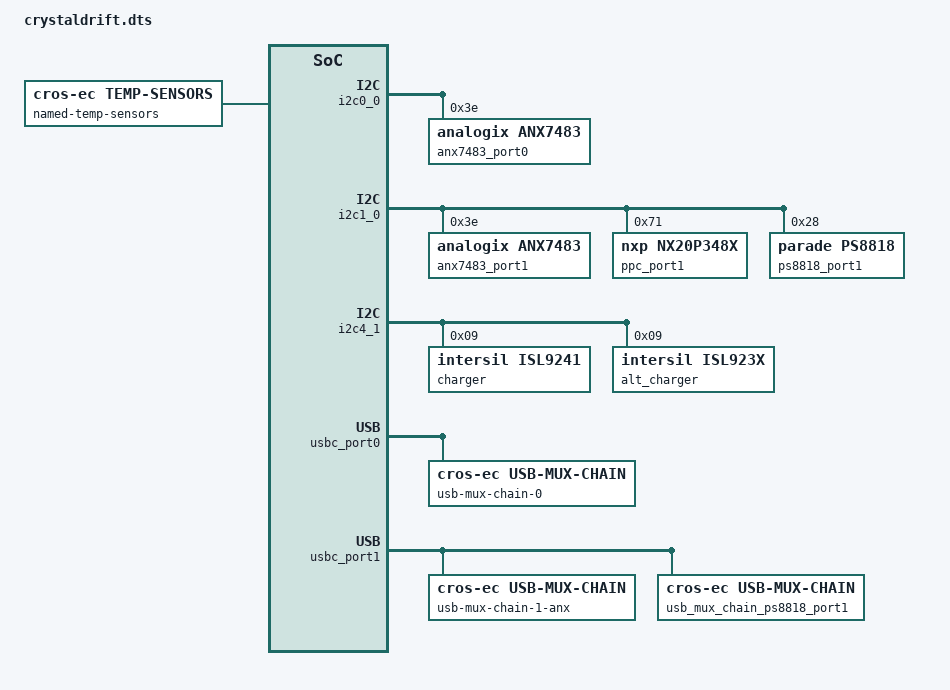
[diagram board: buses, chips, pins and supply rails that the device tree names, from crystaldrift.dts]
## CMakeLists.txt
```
# Copyright 2021 The ChromiumOS Authors
# Use of this source code is governed by a BSD-style license that can be
# found in the LICENSE file.

cmake_minimum_required(VERSION 3.13.1)

find_package(Zephyr REQUIRED HINTS "${ZEPHYR_BASE}")

zephyr_include_directories("${CMAKE_CURRENT_SOURCE_DIR}/include")

zephyr_library_sources("src/common.c")
zephyr_library_sources("src/i2c_policy.c")
zephyr_library_sources("src/power_signals.c")

zephyr_library_sources_ifdef(CONFIG_PLATFORM_EC_USBC
	"src/usb_pd_policy.c"
	"src/usb_mux_config.c"
	"src/usbc_config.c")
zephyr_library_sources_ifdef(CONFIG_PLATFORM_EC_LED_COMMON
	"src/led.c")
zephyr_library_sources_ifdef(CONFIG_PLATFORM_EC_AMD_STT
	"src/stt.c")

if(DEFINED CONFIG_BOARD_SKYRIM)
	project(skyrim)
	add_subdirectory(skyrim)
endif()

if(DEFINED CONFIG_BOARD_WINTERHOLD)
	project(winterhold)
	add_subdirectory(winterhold)
endif()

if(DEFINED CONFIG_BOARD_FROSTFLOW)
	project(frostflow)
	add_subdirectory(frostflow)
endif()

if(DEFINED CONFIG_BOARD_CRYSTALDRIFT)
	project(crystaldrift)
	add_subdirectory(crystaldrift)
endif()

if(DEFINED CONFIG_BOARD_MARKARTH)
	project(markarth)
	add_subdirectory(markarth)
endif()
```

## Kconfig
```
# Copyright 2021 The ChromiumOS Authors
# Use of this source code is governed by a BSD-style license that can be
# found in the LICENSE file.

config BOARD_SKYRIM
	bool "Google Skyrim Board"
	help
	  Build Google Skyrim reference board.  This board uses an AMD SoC
	  and NPCX9 EC

config BOARD_WINTERHOLD
	bool "Google Winterhold Board"
	help
	  Build Google Winterhold reference board.  This board uses an AMD SoC
	  and NPCX9 EC

config BOARD_FROSTFLOW
	bool "Google Frostflow Board"
	help
	  Build Google Frostflow reference board.  This board uses an AMD SoC
	  and NPCX9 EC

config BOARD_CRYSTALDRIFT
	bool "Google Crystaldrift Board"
	help
	  Build Google Crystaldrift reference board.  This board uses an AMD SoC
	  and NPCX9 EC

config BOARD_MARKARTH
	bool "Google Markarth Board"
	help
	  Build Google Markarth reference board.  This board uses an AMD SoC
	  and NPCX9 EC

config BOARD_USB_HUB_RESET
	bool "Support USB hub reset or not"
	default y
	help
	  Enable this if your board has a USB hub reset GPIO connect to EC to
	  reset the USB hub.

module = SKYRIM
module-str = Skyrim board-specific code
source "subsys/logging/Kconfig.template.log_config"

source "Kconfig.zephyr"
```

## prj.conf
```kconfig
# Copyright 2021 The ChromiumOS Authors
# Use of this source code is governed by a BSD-style license that can be
# found in the LICENSE file.

CONFIG_CROS_EC=y
CONFIG_PLATFORM_EC=y
CONFIG_SHIMMED_TASKS=y
CONFIG_ESPI=y

# Shell features
CONFIG_SHELL_HELP=y
CONFIG_SHELL_HISTORY=y
CONFIG_SHELL_TAB=y
CONFIG_SHELL_TAB_AUTOCOMPLETION=y
CONFIG_KERNEL_SHELL=y

# Power sequencing
CONFIG_AP=y
CONFIG_AP_X86_AMD=y
CONFIG_PLATFORM_EC_POWERSEQ=y
CONFIG_PLATFORM_EC_POWER_BUTTON_TO_PCH_CUSTOM=y
CONFIG_PLATFORM_EC_POWER_SLEEP_FAILURE_DETECTION=y
CONFIG_PLATFORM_EC_POWERSEQ_RSMRST_DELAY=y
CONFIG_PLATFORM_EC_POWERSEQ_S0IX=y
CONFIG_PLATFORM_EC_PORT80=y

# Power button
CONFIG_PLATFORM_EC_POWER_BUTTON=y

# CBI
CONFIG_EEPROM=y
CONFIG_PLATFORM_EC_BOARD_VERSION_CBI=y

# Temperature Sensors
CONFIG_PLATFORM_EC_AMD_SB_RMI=y
CONFIG_PLATFORM_EC_AMD_STT=y
CONFIG_PLATFORM_EC_THROTTLE_AP=y

# External power
CONFIG_PLATFORM_EC_HOSTCMD=y
CONFIG_PLATFORM_EC_EXTPOWER_GPIO=y
CONFIG_PLATFORM_EC_BACKLIGHT_LID=y
CONFIG_PLATFORM_EC_BACKLIGHT_LID_ACTIVE_LOW=y

# Sensors
CONFIG_SENSOR=y
CONFIG_SENSOR_SHELL=n

# Lid switch
CONFIG_PLATFORM_EC_LID_ANGLE=y
CONFIG_PLATFORM_EC_LID_ANGLE_UPDATE=y
CONFIG_PLATFORM_EC_LID_SWITCH=y

# Keyboard
CONFIG_PLATFORM_EC_KBLIGHT_ENABLE_PIN=y
CONFIG_PLATFORM_EC_KEYBOARD_COL2_INVERTED=y
CONFIG_PLATFORM_EC_VOLUME_BUTTONS=y
CONFIG_PLATFORM_EC_KEYBOARD_PWRBTN_ASSERTS_KSI3=y
CONFIG_PLATFORM_EC_KEYBOARD_REFRESH_ROW3=y

# Syscon
CONFIG_SYSCON=y

# Battery
CONFIG_PLATFORM_EC_BATTERY_SMART=y
CONFIG_PLATFORM_EC_BATTERY_FUEL_GAUGE=y
CONFIG_PLATFORM_EC_BATTERY_CUT_OFF=y
CONFIG_PLATFORM_EC_BATTERY_REVIVE_DISCONNECT=y

# Charger
CONFIG_PLATFORM_EC_CHARGER_DISCHARGE_ON_AC=y
CONFIG_PLATFORM_EC_CHARGER_DEFAULT_CURRENT_LIMIT=512
CONFIG_PLATFORM_EC_CHARGER_MIN_INPUT_CURRENT_LIMIT=512
CONFIG_PLATFORM_EC_CHARGER_ISL9241=y
CONFIG_PLATFORM_EC_CHARGER_SENSE_RESISTOR=10
CONFIG_PLATFORM_EC_CHARGER_SENSE_RESISTOR_AC=20
CONFIG_PLATFORM_EC_CHARGER_MIN_POWER_MW_FOR_POWER_ON=50000

# USB-C
CONFIG_PLATFORM_EC_USBC_PPC_NX20P3483=y
CONFIG_PLATFORM_EC_USBC_PPC_AOZ1380=y
CONFIG_PLATFORM_EC_USBC_RETIMER_ANX7451=y
CONFIG_PLATFORM_EC_USBC_RETIMER_PS8811=y
CONFIG_PLATFORM_EC_USBC_RETIMER_PS8818=y
CONFIG_PLATFORM_EC_USBC_SS_MUX_DFP_ONLY=y
CONFIG_PLATFORM_EC_USB_MUX_AMD_FP6=y
CONFIG_PLATFORM_EC_USB_MUX_RUNTIME_CONFIG=y
CONFIG_PLATFORM_EC_USB_DRP_ACC_TRYSRC=y
CONFIG_PLATFORM_EC_USB_PID=0x505F
CONFIG_PLATFORM_EC_USB_PD_5V_EN_CUSTOM=y
CONFIG_PLATFORM_EC_USB_PD_VBUS_DETECT_TCPC=y
CONFIG_PLATFORM_EC_USB_PD_DISCHARGE_TCPC=y
CONFIG_PLATFORM_EC_USB_PD_DP_HPD_GPIO=y
CONFIG_PLATFORM_EC_USB_PD_FRS=y
CONFIG_PLATFORM_EC_USB_PD_FRS_TCPC=y
CONFIG_PLATFORM_EC_USB_PD_LOGGING=y
CONFIG_PLATFORM_EC_USB_PD_REV30=y
CONFIG_PLATFORM_EC_USB_PD_TBT_COMPAT_MODE=n
CONFIG_PLATFORM_EC_USB_PD_TCPC_LOW_POWER=y
CONFIG_PLATFORM_EC_USB_PD_TCPM_NCT38XX=y
CONFIG_PLATFORM_EC_USB_PD_TCPC_RUNTIME_CONFIG=n
CONFIG_PLATFORM_EC_USB_PD_USB4=n
CONFIG_PLATFORM_EC_USB_PD_VBUS_MEASURE_CHARGER=y
# Give ourselves enough task space to use i2ctrace
CONFIG_TASK_PD_STACK_SIZE=1280

# Motion sense
CONFIG_PLATFORM_EC_MOTIONSENSE=y
CONFIG_PLATFORM_EC_ACCEL_FIFO=y
CONFIG_PLATFORM_EC_CONSOLE_CMD_ACCELS=y
CONFIG_PLATFORM_EC_CONSOLE_CMD_ACCEL_INFO=y
CONFIG_PLATFORM_EC_LID_ANGLE=y
CONFIG_PLATFORM_EC_LID_ANGLE_UPDATE=y
CONFIG_PLATFORM_EC_SENSOR_TIGHT_TIMESTAMPS=y

CONFIG_PLATFORM_EC_MKBP_EVENT=y
CONFIG_PLATFORM_EC_MKBP_INPUT_DEVICES=y
CONFIG_PLATFORM_EC_MKBP_USE_GPIO=y

CONFIG_PLATFORM_EC_TABLET_MODE=y
CONFIG_PLATFORM_EC_TABLET_MODE_SWITCH=y
CONFIG_PLATFORM_EC_GMR_TABLET_MODE=y

CONFIG_PLATFORM_EC_ACCEL_BMA4XX=y
CONFIG_PLATFORM_EC_ACCELGYRO_BMI3XX=y
CONFIG_PLATFORM_EC_ACCELGYRO_BMI_COMM_I2C=y

# Misc.
CONFIG_PLATFORM_EC_I2C_DEBUG=y
CONFIG_PLATFORM_EC_PORT80_4_BYTE=y

# These are debug options that happen to be expensive in terms of flash space.
# Turn on as needed based on demand.
CONFIG_FLASH_PAGE_LAYOUT=n # 1876 bytes
CONFIG_FLASH_SHELL=n # 1852 bytes
CONFIG_PLATFORM_EC_CONSOLE_CMD_ACCEL_INFO=n # 656 bytes
CONFIG_PLATFORM_EC_CONSOLE_CMD_MEM=n # 896 bytes
# CONFIG_PLATFORM_EC_CONSOLE_CMD_TCPC_DUMP=n # 1180 bytes
CONFIG_PLATFORM_EC_CONSOLE_CMD_USB_PD_CABLE=n # 1104 bytes
CONFIG_THREAD_MONITOR=n # 1548 bytes
```

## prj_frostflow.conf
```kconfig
# Copyright 2022 The ChromiumOS Authors
# Use of this source code is governed by a BSD-style license that can be
# found in the LICENSE file.

# Frostflow reference-board-specific Kconfig settings.
CONFIG_BOARD_FROSTFLOW=y
CONFIG_PLATFORM_EC_CHARGER_INPUT_CURRENT_DERATE_PCT=10

# TODO(b/215404321): Remove later in board development
CONFIG_PLATFORM_EC_EEPROM_CBI_WP=y
CONFIG_PLATFORM_EC_SYSTEM_UNLOCKED=n

# LED
CONFIG_PLATFORM_EC_LED_DT=y

# Frostflow is capable of sinking 45W
CONFIG_PLATFORM_EC_PD_MAX_POWER_MW=45000
CONFIG_PLATFORM_EC_PD_MAX_CURRENT_MA=3000
CONFIG_PLATFORM_EC_PD_MAX_VOLTAGE_MV=20000
CONFIG_PLATFORM_EC_CHARGER_MIN_POWER_MW_FOR_POWER_ON=15000

# Keyboard
CONFIG_PLATFORM_EC_KEYBOARD_CUSTOMIZATION=y

# Frostflow not have the USB HUB
CONFIG_BOARD_USB_HUB_RESET=n

# Battery
CONFIG_PLATFORM_EC_BATTERY_PRESENT_GPIO=y

# Fan
CONFIG_PLATFORM_EC_FAN=y
CONFIG_PLATFORM_EC_CUSTOM_FAN_CONTROL=y
```

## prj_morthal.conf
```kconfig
# Copyright 2022 The ChromiumOS Authors
# Use of this source code is governed by a BSD-style license that can be
# found in the LICENSE file.

# Morthal reference-board-specific Kconfig settings.
CONFIG_BOARD_MORTHAL=y

# TODO(b/215404321): Remove later in board development
CONFIG_PLATFORM_EC_EEPROM_CBI_WP=y
CONFIG_PLATFORM_EC_SYSTEM_UNLOCKED=y

# LED
CONFIG_PLATFORM_EC_LED_DT=y

# Morthal is capable of sinking 100W
CONFIG_PLATFORM_EC_PD_MAX_POWER_MW=100000
CONFIG_PLATFORM_EC_PD_MAX_CURRENT_MA=5000
CONFIG_PLATFORM_EC_PD_MAX_VOLTAGE_MV=20000

# Only Morthal has the PCT2075
CONFIG_PLATFORM_EC_TEMP_SENSOR_PCT2075=y

CONFIG_PLATFORM_EC_USBC_RETIMER_ANX7483=y

# Battery
CONFIG_PLATFORM_EC_BATTERY_PRESENT_GPIO=y
```

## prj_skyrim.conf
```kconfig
# Copyright 2021 The ChromiumOS Authors
# Use of this source code is governed by a BSD-style license that can be
# found in the LICENSE file.

# Skyrim reference-board-specific Kconfig settings.
CONFIG_BOARD_SKYRIM=y

# CBI WP pin present
CONFIG_PLATFORM_EC_EEPROM_CBI_WP=y

# LED
CONFIG_PLATFORM_EC_LED_DT=y

# Skyrim is capable of sinking 100W
CONFIG_PLATFORM_EC_PD_MAX_POWER_MW=100000
CONFIG_PLATFORM_EC_PD_MAX_CURRENT_MA=5000
CONFIG_PLATFORM_EC_PD_MAX_VOLTAGE_MV=20000

# Only Skyrim has the PCT2075
CONFIG_PLATFORM_EC_TEMP_SENSOR_PCT2075=y

CONFIG_PLATFORM_EC_USBC_RETIMER_ANX7483=y

# Enable alternative charger chip
CONFIG_PLATFORM_EC_CHARGER_RUNTIME_CONFIG=y
CONFIG_PLATFORM_EC_CHARGER_ISL9238C=y

# Battery
CONFIG_PLATFORM_EC_BATTERY_PRESENT_GPIO=y
```

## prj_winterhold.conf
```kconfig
# Copyright 2022 The ChromiumOS Authors
# Use of this source code is governed by a BSD-style license that can be
# found in the LICENSE file.

# Winterhold reference-board-specific Kconfig settings.
CONFIG_BOARD_WINTERHOLD=y

# TODO(b/215404321): Remove later in board development
CONFIG_PLATFORM_EC_EEPROM_CBI_WP=y
CONFIG_PLATFORM_EC_SYSTEM_UNLOCKED=y

# LED
CONFIG_PLATFORM_EC_LED_DT=y

CONFIG_PLATFORM_EC_USBC_RETIMER_ANX7483=y

# Enable charger chip
CONFIG_PLATFORM_EC_CHARGER_ISL9238=y
CONFIG_PLATFORM_EC_CHARGER_ISL9241=n

# Get the vbus voltage from TCPC
CONFIG_PLATFORM_EC_USB_PD_VBUS_MEASURE_CHARGER=n
CONFIG_PLATFORM_EC_USB_PD_VBUS_MEASURE_TCPC=y

# Remove unused sensor
CONFIG_PLATFORM_EC_ACCEL_BMA4XX=n

# Support LIS2DW12 sensor
CONFIG_PLATFORM_EC_ACCEL_LIS2DW12=y

# Disable lid configuration
CONFIG_PLATFORM_EC_LID_ANGLE=n
CONFIG_PLATFORM_EC_LID_ANGLE_UPDATE=n

# Disable tablet mode configuration
CONFIG_PLATFORM_EC_TABLET_MODE=n
CONFIG_PLATFORM_EC_TABLET_MODE_SWITCH=n
CONFIG_PLATFORM_EC_GMR_TABLET_MODE=n

# Battery
CONFIG_PLATFORM_EC_BATTERY_HW_PRESENT_CUSTOM=y
```

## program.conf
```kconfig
# Copyright 2021 The ChromiumOS Authors
# Use of this source code is governed by a BSD-style license that can be
# found in the LICENSE file.

CONFIG_CROS_EC=y
CONFIG_PLATFORM_EC=y
CONFIG_ESPI=y

# Shell features
CONFIG_PLATFORM_EC_ISR_CONSOLE_OUTPUT=n
CONFIG_SHELL_HISTORY=y
CONFIG_SHELL_TAB=y
CONFIG_SHELL_TAB_AUTOCOMPLETION=y
CONFIG_KERNEL_SHELL=y

# Power sequencing
CONFIG_AP=y
CONFIG_AP_X86_AMD=y
CONFIG_PLATFORM_EC_CHIPSET_RESET_HOOK=y
CONFIG_PLATFORM_EC_POWERSEQ=y
CONFIG_PLATFORM_EC_POWER_BUTTON_TO_PCH_CUSTOM=y
CONFIG_PLATFORM_EC_POWER_SLEEP_FAILURE_DETECTION=y
CONFIG_PLATFORM_EC_POWERSEQ_RSMRST_DELAY=y
CONFIG_PLATFORM_EC_POWERSEQ_S0IX=y
CONFIG_PLATFORM_EC_POWERSEQ_CPU_PROCHOT_ACTIVE_LOW=y
CONFIG_PLATFORM_EC_PORT80=y

# Power button
CONFIG_PLATFORM_EC_POWER_BUTTON=y

# CBI
CONFIG_EEPROM=y
CONFIG_PLATFORM_EC_BOARD_VERSION_CBI=y
CONFIG_PLATFORM_EC_EEPROM_CBI_WP=y

# Temperature Sensors
CONFIG_PLATFORM_EC_AMD_SB_RMI=y
CONFIG_PLATFORM_EC_AMD_STT=y
CONFIG_PLATFORM_EC_THROTTLE_AP=y
# An external prochot can only be triggered by the charger
# and during on the fan would increase current draw and make it worse.
CONFIG_PLATFORM_EC_THROTTLE_AP_NO_FAN=y
CONFIG_PLATFORM_EC_THROTTLE_AP_SINGLE_PIN=y

# External power
CONFIG_PLATFORM_EC_HOSTCMD=y
CONFIG_HCDEBUG_OFF=y
CONFIG_PLATFORM_EC_EXTPOWER_GPIO=y
CONFIG_PLATFORM_EC_BACKLIGHT_LID=y
CONFIG_PLATFORM_EC_BACKLIGHT_LID_ACTIVE_LOW=y

# Lid switch
CONFIG_PLATFORM_EC_LID_ANGLE=y
CONFIG_PLATFORM_EC_LID_ANGLE_UPDATE=y
CONFIG_PLATFORM_EC_LID_SWITCH=y

# Keyboard
CONFIG_PLATFORM_EC_KEYBOARD_PROTOCOL_8042=y
CONFIG_PLATFORM_EC_KBLIGHT_ENABLE_PIN=y
CONFIG_PLATFORM_EC_KBLIGHT_HOOK_INIT=y
CONFIG_PLATFORM_EC_KEYBOARD_COL2_INVERTED=y
CONFIG_PLATFORM_EC_VOLUME_BUTTONS=y
CONFIG_PLATFORM_EC_KEYBOARD_REFRESH_ROW3=y

# Syscon
CONFIG_SYSCON=y

# Battery
CONFIG_PLATFORM_EC_BATTERY_FUEL_GAUGE=y
CONFIG_PLATFORM_EC_BATTERY_CUT_OFF=y
CONFIG_PLATFORM_EC_BATTERY_REVIVE_DISCONNECT=y
CONFIG_PLATFORM_EC_SMBUS_PEC=y

# Charger
CONFIG_PLATFORM_EC_CHARGER_DISCHARGE_ON_AC=y
CONFIG_PLATFORM_EC_CHARGER_DEFAULT_CURRENT_LIMIT=512
CONFIG_PLATFORM_EC_CHARGER_ISL9241=y
CONFIG_PLATFORM_EC_CHARGER_DUMP_PROCHOT=y
CONFIG_PLATFORM_EC_CHARGER_SENSE_RESISTOR=10
CONFIG_PLATFORM_EC_CHARGER_SENSE_RESISTOR_AC=20
CONFIG_PLATFORM_EC_CHARGER_SET_FREQUENCY=y
CONFIG_PLATFORM_EC_CHARGER_MIN_POWER_MW_FOR_POWER_ON=50000
CONFIG_PLATFORM_EC_CHARGER_AC_PROCHOT_CURRENT_MA=3328
CONFIG_PLATFORM_EC_CHARGER_DC_PROCHOT_CURRENT_MA=6570

# USB-C
CONFIG_PLATFORM_EC_USBC_RETIMER_ANX7451=y
CONFIG_PLATFORM_EC_USBC_RETIMER_PS8811=y
CONFIG_PLATFORM_EC_USBC_SS_MUX_DFP_ONLY=y
CONFIG_PLATFORM_EC_USB_MUX_RUNTIME_CONFIG=y
CONFIG_PLATFORM_EC_USB_DRP_ACC_TRYSRC=y
CONFIG_PLATFORM_EC_USB_PID=0x505F
CONFIG_PLATFORM_EC_USB_PD_5V_EN_CUSTOM=y
CONFIG_PLATFORM_EC_USB_PD_VBUS_DETECT_TCPC=y
CONFIG_PLATFORM_EC_USB_PD_DISCHARGE_TCPC=y
CONFIG_PLATFORM_EC_USB_PD_DP_HPD_GPIO=y
CONFIG_PLATFORM_EC_USB_PD_FRS=y
CONFIG_PLATFORM_EC_USB_PD_FRS_TCPC=y
CONFIG_PLATFORM_EC_USB_PD_LOGGING=y
CONFIG_PLATFORM_EC_USB_PD_REV30=y
CONFIG_PLATFORM_EC_USB_PD_TBT_COMPAT_MODE=n
CONFIG_PLATFORM_EC_USB_PD_TCPC_LOW_POWER=y
CONFIG_PLATFORM_EC_USB_PD_TCPC_RUNTIME_CONFIG=n
CONFIG_PLATFORM_EC_USB_PD_USB4=n
CONFIG_PLATFORM_EC_USB_PD_VBUS_MEASURE_CHARGER=y
# Give ourselves enough task space to use i2ctrace
CONFIG_TASK_PD_STACK_SIZE=1280

# Motion sense
CONFIG_PLATFORM_EC_MAX_SENSOR_FREQ_MILLIHZ=100000
CONFIG_PLATFORM_EC_ACCEL_FIFO=y
CONFIG_PLATFORM_EC_CONSOLE_CMD_ACCELS=y
CONFIG_PLATFORM_EC_CONSOLE_CMD_ACCEL_INFO=y
CONFIG_PLATFORM_EC_LID_ANGLE=y
CONFIG_PLATFORM_EC_LID_ANGLE_UPDATE=y
CONFIG_PLATFORM_EC_SENSOR_TIGHT_TIMESTAMPS=y

CONFIG_PLATFORM_EC_MKBP_EVENT=y
CONFIG_PLATFORM_EC_MKBP_INPUT_DEVICES=y
CONFIG_PLATFORM_EC_MKBP_USE_GPIO=y

CONFIG_PLATFORM_EC_TABLET_MODE=y
CONFIG_PLATFORM_EC_TABLET_MODE_SWITCH=y
CONFIG_PLATFORM_EC_GMR_TABLET_MODE=y

CONFIG_PLATFORM_EC_ACCELGYRO_BMI3XX=y
CONFIG_PLATFORM_EC_ACCELGYRO_BMI_COMM_I2C=y

# Misc.
CONFIG_PLATFORM_EC_AMD_STB_DUMP=y
CONFIG_PLATFORM_EC_EMULATED_SYSRQ=y
CONFIG_PLATFORM_EC_PORT80_4_BYTE=y
# I2C passthrough isn't used on skyrim
CONFIG_PLATFORM_EC_I2C_PASSTHRU_RESTRICTED=y

# Watchdog
CONFIG_PLATFORM_EC_WATCHDOG_PERIOD_MS=2000

# These are debug options that happen to be expensive in terms of flash space.
# Turn on as needed based on demand.
CONFIG_PLATFORM_EC_ACCEL_SPOOF_MODE=y # 548 bytes
CONFIG_PLATFORM_EC_CONSOLE_CMD_ACCEL_INFO=n # 656 bytes
CONFIG_PLATFORM_EC_CONSOLE_CMD_MEM=n # 896 bytes
CONFIG_PLATFORM_EC_CONSOLE_CMD_TCPC_DUMP=n # 1180 bytes
CONFIG_PLATFORM_EC_CONSOLE_CMD_USB_PD_CABLE=n # 1104 bytes
CONFIG_SHELL_HELP=n # 3432 bytes
CONFIG_THREAD_MONITOR=n # 1548 bytes
CONFIG_PLATFORM_EC_DEBUG_ASSERT=n

# CME
CONFIG_PLATFORM_EC_CME_VERSION=1

# Save some firmware space
CONFIG_SHELL_HELP=n
CONFIG_SHELL_TAB=n
CONFIG_SHELL_TAB_AUTOCOMPLETION=n
CONFIG_PLATFORM_EC_CONSOLE_CMD_ACCELS=n
CONFIG_PLATFORM_EC_CONSOLE_CMD_APTHROTTLE=n
CONFIG_PLATFORM_EC_CONSOLE_CMD_FLASH=n
CONFIG_PLATFORM_EC_CONSOLE_CMD_MEM=n
```

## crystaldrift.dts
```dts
/* Copyright 2022 The ChromiumOS Authors
 * Use of this source code is governed by a BSD-style license that can be
 * found in the LICENSE file.
 */

#include <dt-bindings/usbc_mux.h>

#include "i2c_common.dtsi"

/ {
	named-gpios {
		/* Crystaldrift-specific GPIO customizations */
	};

	named-temp-sensors {
		compatible = "cros-ec,temp-sensors";
		soc-pct2075 {
			temp_host_high = <100>;
			temp_host_halt = <105>;
			temp_host_release_high = <80>;
			temp_host_release_halt = <80>;
			temp_fan_off = <35>;
			temp_fan_max = <70>;
			power-good-pin = <&gpio_pg_pwr_s5>;
			sensor = <&soc_pct2075>;
		};
		amb-pct2075 {
			power-good-pin = <&gpio_pg_pwr_s5>;
			sensor = <&amb_pct2075>;
		};
	};

	/*
	 * Note this is expected to vary per-board, so we keep it in the board
	 * dts files.
	 */
	crystaldrift-fw-config {
		compatible = "cros-ec,cbi-fw-config";

		form-factor {
			enum-name = "FW_FORM_FACTOR";
			start = <0>;
			size = <1>;

			ff-clamshell {
				compatible = "cros-ec,cbi-fw-config-value";
				enum-name = "FW_FF_CLAMSHELL";
				value = <0>;
			};
			ff-convertible {
				compatible = "cros-ec,cbi-fw-config-value";
				enum-name = "FW_FF_CONVERTIBLE";
				value = <1>;
				default;
			};
		};
		io-db {
			enum-name = "FW_IO_DB";
			start = <6>;
			size = <2>;

			io-db-ps8811-ps8818 {
				compatible = "cros-ec,cbi-fw-config-value";
				enum-name = "FW_IO_DB_PS8811_PS8818";
				value = <0>;
			};
			io-db-none-anx7483 {
				compatible = "cros-ec,cbi-fw-config-value";
				enum-name = "FW_IO_DB_NONE_ANX7483";
				value = <1>;
				default;
			};
		};

		/*
		 * FW_CONFIG field to enable fan or not.
		 */
		fan {
			enum-name = "FW_FAN";
			start = <10>;
			size = <1>;

			no-fan {
				compatible = "cros-ec,cbi-fw-config-value";
				enum-name = "FW_FAN_NOT_PRESENT";
				value = <0>;
			};
			fan-present {
				compatible = "cros-ec,cbi-fw-config-value";
				enum-name = "FW_FAN_PRESENT";
				value = <1>;
				/*
				 * Set as default so that unprovisioned
				 * configs will run the fan regardless.
				 */
				default;
			};
		};

		charger-option {
			enum-name = "FW_CHARGER";
			start = <11>;
			size = <2>;

			charger-option-isl9241 {
				compatible = "cros-ec,cbi-fw-config-value";
				enum-name = "FW_CHARGER_ISL9241";
				value = <0>;
				default;
			};
			charger-option-isl9538 {
				compatible = "cros-ec,cbi-fw-config-value";
				enum-name = "FW_CHARGER_ISL9538";
				value = <1>;
			};
		};
	};

	/* Rotation matrices for motion sensors. */
	motionsense-rotation-ref {
		compatible = "cros-ec,motionsense-rotation-ref";
		lid_rot_ref: lid-rotation-ref {
			mat33 = <0 (-1) 0
				 1 0 0
				 0 0 1>;
		};

		lid_rot_ref1: lid-rotation-ref1 {
			mat33 = <0 1 0
				 (-1) 0 0
				 0 0 1>;
		};

		base_rot_ref: base-rotation-ref {
			mat33 = <0 1 0
				 (-1) 0 0
				 0 0 1>;
		};
	};

	ppc_port0: aoz1380 {
		compatible = "aoz,aoz1380";
		status = "okay";
	};
};

&i2c0_0 {
	anx7483_port0: anx7483@3e {
		compatible = "analogix,anx7483";
		reg = <0x3e>;
		board-set = "board_anx7483_c0_mux_set";
		flags = <USB_MUX_FLAG_RESETS_IN_G3>;
	};
};

&i2c1_0 {
	anx7483_port1: anx7483@3e {
		compatible = "analogix,anx7483";
		reg = <0x3e>;
		board-set = "board_anx7483_c1_mux_set";
		flags = <USB_MUX_FLAG_RESETS_IN_G3>;
	};
	ppc_port1: nx20p348x@71 {
		compatible = "nxp,nx20p348x";
		status = "okay";
		reg = <0x71>;
	};
	ps8818_port1: ps8818@28 {
		compatible = "parade,ps8818";
		reg = <0x28>;
		flags = <(USB_MUX_FLAG_RESETS_IN_G3)>;
		board-set = "board_c1_ps8818_mux_set";
	};
};

&i2c4_1 {
	charger: isl9241@9 {
		compatible = "intersil,isl9241";
		status = "okay";
		reg = <0x9>;
	};
	alt_charger: isl9538@9 {
		compatible = "intersil,isl923x";
		status = "okay";
		reg = <0x9>;
	};
};

&usbc_port0 {
	chg_alt = <&alt_charger>;
	ppc = <&ppc_port0>;
	usb-mux-chain-0 {
		compatible = "cros-ec,usb-mux-chain";
		usb-muxes = <&amd_fp6_port0 &anx7483_port0>;
	};
};

&usbc_port1 {
	ppc = <&ppc_port1>;
	usb-mux-chain-1-anx {
		compatible = "cros-ec,usb-mux-chain";
		usb-muxes = <&amd_fp6_port1 &anx7483_port1>;
	};
	usb_mux_chain_ps8818_port1: usb-mux-chain-1-ps {
		compatible = "cros-ec,usb-mux-chain";
		usb-muxes = <&amd_fp6_port1 &ps8818_port1>;
		alternative-chain;
	};
};
```

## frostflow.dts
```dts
/* Copyright 2022 The ChromiumOS Authors
 * Use of this source code is governed by a BSD-style license that can be
 * found in the LICENSE file.
 */

#include <dt-bindings/usbc_mux.h>

#include "i2c_common.dtsi"

/ {
	named-gpios {
		/* Frostflow-specific GPIO customizations */
	};

	named-temp-sensors {
		compatible = "cros-ec,temp-sensors";
		temp_soc: soc-pct2075 {
			temp_host_high = <75>;
			temp_host_halt = <80>;
			temp_host_release_high = <65>;
			temp_host_release_halt = <70>;
			power-good-pin = <&gpio_pg_pwr_s5>;
			sensor = <&soc_pct2075>;
		};
		temp_amb: amb-pct2075 {
			temp_host_high = <65>;
			temp_host_halt = <70>;
			temp_host_release_high = <55>;
			temp_host_release_halt = <60>;
			temp_fan_off = <32>;
			temp_fan_max = <45>;
			power-good-pin = <&gpio_pg_pwr_s5>;
			sensor = <&amb_pct2075>;
		};
	};

	/* Rotation matrices for motion sensors. */
	motionsense-rotation-ref {
		compatible = "cros-ec,motionsense-rotation-ref";
		lid_rot_ref: lid-rotation-ref {
			mat33 = <1 0 0
				 0 1 0
				 0 0 1>;
		};

		base_rot_ref: base-rotation-ref {
			mat33 = <0 1 0
				 1 0 0
				 0 0 (-1)>;
		};
	};

	ppc_port0: aoz1380 {
		compatible = "aoz,aoz1380";
		status = "okay";
	};

	fan_steps_clamshell: fan-steps-clamshell {
		compatible = "cros-ec,fan-steps";
		level_0 {
			temp_on = <(-1) (-1) (-1) (-1) 31>;
			temp_off = <(-1) (-1) (-1) (-1) 99>;
			rpm_target = <0>;
		};
		level_1 {
			temp_on = <(-1) (-1) (-1) (-1) 32>;
			temp_off = <(-1) (-1) (-1) (-1) 30>;
			rpm_target = <2600>;
		};
		level_2 {
			temp_on = <(-1) (-1) (-1) (-1) 34>;
			temp_off = <(-1) (-1) (-1) (-1) 31>;
			rpm_target = <2900>;
		};
		level_3 {
			temp_on = <(-1) (-1) (-1) (-1) 36>;
			temp_off = <(-1) (-1) (-1) (-1) 33>;
			rpm_target = <3600>;
		};
		level_4 {
			temp_on = <(-1) (-1) (-1) (-1) 38>;
			temp_off = <(-1) (-1) (-1) (-1) 35>;
			rpm_target = <4200>;
		};
		level_5 {
			temp_on = <(-1) (-1) (-1) (-1) 45>;
			temp_off = <(-1) (-1) (-1) (-1) 37>;
			rpm_target = <4600>;
		};
	};

	fan_steps_tablet: fan-steps-tablet {
		compatible = "cros-ec,fan-steps";
		level_0 {
			temp_on = <(-1) (-1) (-1) (-1) 31>;
			temp_off = <(-1) (-1) (-1) (-1) 99>;
			rpm_target = <0>;
		};
		level_1 {
			temp_on = <(-1) (-1) (-1) (-1) 32>;
			temp_off = <(-1) (-1) (-1) (-1) 30>;
			rpm_target = <2600>;
		};
		level_2 {
			temp_on = <(-1) (-1) (-1) (-1) 34>;
			temp_off = <(-1) (-1) (-1) (-1) 31>;
			rpm_target = <2900>;
		};
		level_3 {
			temp_on = <(-1) (-1) (-1) (-1) 36>;
			temp_off = <(-1) (-1) (-1) (-1) 33>;
			rpm_target = <3600>;
		};
		level_4 {
			temp_on = <(-1) (-1) (-1) (-1) 38>;
			temp_off = <(-1) (-1) (-1) (-1) 35>;
			rpm_target = <4200>;
		};
		level_5 {
			temp_on = <(-1) (-1) (-1) (-1) 45>;
			temp_off = <(-1) (-1) (-1) (-1) 37>;
			rpm_target = <4600>;
		};
	};
};

&i2c1_0 {
	ppc_port1: nx20p348x@71 {
		compatible = "nxp,nx20p348x";
		status = "okay";
		reg = <0x71>;
	};
	ps8818_port1: ps8818@28 {
		compatible = "parade,ps8818";
		reg = <0x28>;
		flags = <(USB_MUX_FLAG_RESETS_IN_G3)>;
		board-set = "board_c1_ps8818_mux_set";
	};
};

&i2c4_1 {
	charger: isl9241@9 {
		compatible = "intersil,isl9241";
		status = "okay";
		reg = <0x9>;
	};
};

&amd_fp6_port0 {
	board-set = "board_c0_amd_fp6_mux_set";
};

&usbc_port0 {
	ppc = <&ppc_port0>;
	usb-mux-chain-0 {
		compatible = "cros-ec,usb-mux-chain";
		usb-muxes = <&amd_fp6_port0>;
	};
};

&usbc_port1 {
	ppc = <&ppc_port1>;
	usb-mux-chain-1-ps8818 {
		compatible = "cros-ec,usb-mux-chain";
		usb-muxes = <&amd_fp6_port1 &ps8818_port1>;
	};
};

&cros_kb_raw {
	pinctrl-0 = <
		&ksi0_gp31
		&ksi1_gp30
		&ksi2_gp27
		&ksi3_gp26
		&ksi4_gp25
		&ksi5_gp24
		&ksi6_gp23
		&ksi7_gp22
		&kso00_gp21
		&kso01_gp20
		&kso03_gp16
		&kso04_gp15
		&kso05_gp14
		&kso06_gp13
		&kso07_gp12
		&kso08_gp11
		&kso09_gp10
		&kso10_gp07
		&kso11_gp06
		&kso12_gp05
		&kso13_gp04
		&kso14_gp82
	>;
};

&temp_sensor_charger {
	temp_host_high = <75>;
	temp_host_halt = <80>;
	temp_host_release_high = <65>;
	temp_host_release_halt = <70>;
};

&temp_sensor_memory {
	temp_host_high = <75>;
	temp_host_halt = <80>;
	temp_host_release_high = <65>;
	temp_host_release_halt = <70>;
};

&temp_sensor_cpu {
	/delete-property/ temp_host_high;
	/delete-property/ temp_host_halt;
	/delete-property/ temp_host_release_high;
	/delete-property/ temp_fan_off;
	/delete-property/ temp_fan_max;
};

&fan0 {
	pwms = <&pwm0 0 PWM_KHZ(25) PWM_POLARITY_NORMAL>;
	rpm_min = <2400>;
	rpm_start = <2600>;
	rpm_max = <4600>;
};
```

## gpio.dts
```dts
/* Copyright 2021 The ChromiumOS Authors
 * Use of this source code is governed by a BSD-style license that can be
 * found in the LICENSE file.
 */

/ {
	aliases {
		gpio-wp = &gpio_wp;
		gpio-cbi-wp = &gpio_cbi_wp;
		gpio-kbd-kso2 = &gpio_ec_kso_02_inv;
	};

	/* GPIOs shared by all boards */
	named-gpios {
		compatible = "named-gpios";

		ccd_mode_odl {
			gpios = <&gpioc 6 GPIO_ODR_HIGH>;
		};
		ec_gsc_packet_mode {
			gpios = <&gpiob 1 GPIO_OUTPUT_LOW>;
			enum-name = "GPIO_PACKET_MODE_EN";
		};
		gpio_mech_pwr_btn_odl: mech_pwr_btn_odl {
			gpios = <&gpiod 2 GPIO_INPUT>;
			enum-name = "GPIO_POWER_BUTTON_L";
		};
		gpio_slp_s3_l: slp_s3_l {
			gpios = <&gpio6 1 GPIO_INPUT>;
			enum-name = "GPIO_PCH_SLP_S3_L";
			alias = "GPIO_PCH_SLP_S0_L";
		};
		gpio_slp_s5_l: slp_s5_l {
			gpios = <&gpio7 2 GPIO_INPUT>;
			enum-name = "GPIO_PCH_SLP_S5_L";
		};
		gpio_pg_pwr_s5: pg_pwr_s5 {
			gpios = <&gpioc 0 GPIO_INPUT>;
			enum-name = "GPIO_S5_PGOOD";
		};
		gpio_s0_pgood: pg_pcore_s0_r_od {
			gpios = <&gpiob 6 GPIO_INPUT>;
			enum-name = "GPIO_S0_PGOOD";
		};
		gpio_acok_od: acok_od {
			gpios = <&gpio0 0 GPIO_INPUT>;
			enum-name = "GPIO_AC_PRESENT";
		};
		gpio_en_pwr_s5: en_pwr_s5 {
			gpios = <&gpiob 7 GPIO_OUTPUT_LOW>;
			enum-name = "GPIO_EN_PWR_A";
		};
		gpio_en_pwr_s0_r: en_pwr_s0_r {
			gpios = <&gpiof 1 GPIO_OUTPUT_LOW>;
		};
		gpio_en_pwr_pcore_s0_r: en_pwr_pcore_s0_r {
			gpios = <&gpioe 1 GPIO_OUTPUT_LOW>;
		};
		ec_sys_rst_l {
			gpios = <&gpio7 6 GPIO_ODR_HIGH>;
			enum-name = "GPIO_SYS_RESET_L";
		};
		gpio_ec_soc_rsmrst_l: ec_soc_rsmrst_l {
			gpios = <&gpioc 5 GPIO_OUTPUT_LOW>;
			enum-name = "GPIO_PCH_RSMRST_L";
		};
		gpio_ec_pch_wake_odl: ec_soc_wake_l {
			gpios = <&gpio0 3 GPIO_OUTPUT_HIGH>;
		};
		prochot_odl {
			gpios = <&gpiod 5 GPIO_ODR_HIGH>;
			enum-name = "GPIO_CPU_PROCHOT";
		};
		soc_alert_ec_l {
			gpios = <&gpioe 2 GPIO_INPUT>;
		};
		gpio_usb_c0_tcpc_int_odl: usb_c0_tcpc_int_odl {
			gpios = <&gpioe 0 GPIO_INPUT>;
			enum-name = "GPIO_USB_C0_TCPC_INT_ODL";
		};
		gpio_usb_c1_tcpc_int_odl: usb_c1_tcpc_int_odl {
			gpios = <&gpioc 7 GPIO_INPUT>;
			enum-name = "GPIO_USB_C1_TCPC_INT_ODL";
		};
		gpio_usb_c0_ppc_int_odl: usb_c0_ppc_int_odl {
			gpios = <&gpio7 5 GPIO_INPUT>;
			enum-name = "GPIO_USB_C0_PPC_INT_ODL";
		};
		gpio_usb_c1_ppc_int_odl: usb_c1_ppc_int_odl {
			gpios = <&gpiod 4 GPIO_INPUT>;
			enum-name = "GPIO_USB_C1_PPC_INT_ODL";
		};
		gpio_usb_c0_bc12_int_odl: usb_c0_bc12_int_odl {
			gpios = <&gpioa 4 GPIO_INPUT_PULL_UP>;
			enum-name = "GPIO_USB_C0_BC12_INT_ODL";
		};
		gpio_usb_c1_bc12_int_odl: usb_c1_bc12_int_odl {
			gpios = <&gpio9 6 GPIO_INPUT_PULL_UP>;
			enum-name = "GPIO_USB_C1_BC12_INT_ODL";
		};
		gpio_usb_c0_tcpc_rst_l: usb_c0_tcpc_rst_l {
			gpios = <&gpio3 4 GPIO_OUTPUT_HIGH>;
			enum-name = "GPIO_USB_C0_TCPC_RST_L";
		};
		gpio_usb_c1_tcpc_rst_l: usb_c1_tcpc_rst_l {
			gpios = <&gpio3 7 GPIO_OUTPUT_HIGH>;
			enum-name = "GPIO_USB_C1_TCPC_RST_L";
		};
		usb_c0_hpd {
			gpios = <&gpiof 5 GPIO_OUTPUT_LOW>;
			enum-name = "GPIO_USB_C0_DP_HPD";
		};
		usb_c1_hpd {
			gpios = <&gpiof 4 GPIO_OUTPUT_LOW>;
			enum-name = "GPIO_USB_C1_DP_HPD";
		};
		gpio_lid_open: lid_open {
			gpios = <&gpio0 2 GPIO_INPUT>;
			enum-name = "GPIO_LID_OPEN";
		};
		gpio_ec_batt_pres_odl: ec_batt_pres_odl {
			gpios = <&gpio9 4 GPIO_INPUT>;
			enum-name = "GPIO_BATT_PRES_ODL";
		};
		gpio_ec_disable_disp_bl: ec_disable_disp_bl {
			gpios = <&gpioa 6 GPIO_OUTPUT_HIGH>;
			enum-name = "GPIO_ENABLE_BACKLIGHT_L";
		};
		gpio_usb_fault_odl: usb_fault_odl {
			gpios = <&gpio5 0 (GPIO_ODR_HIGH | GPIO_VOLTAGE_1P8)>;
		};
		gpio_en_pwr_s3: en_pwr_s3 {
			gpios = <&gpio7 4 GPIO_OUTPUT_LOW>;
		};
		gpio_pg_groupc_s0_od: pg_groupc_s0_od {
			gpios = <&gpiof 0 GPIO_INPUT>;
		};
		gpio_ec_i2c_usbc_pd_int: ec_i2c_usbc_pd_int {
			gpios = <&gpioa 3 GPIO_INPUT>;
		};
		gpio_soc_thermtrip_odl: soc_thermtrip_odl {
			gpios = <&gpio9 5 GPIO_INPUT>;
		};
		gpio_hub_rst: hub_rst {
			gpios = <&gpio6 6 GPIO_OUTPUT_HIGH>;
		};
		ec_soc_int_l {
			gpios = <&gpioa 1 GPIO_OUTPUT_HIGH>;
			enum-name = "GPIO_EC_INT_L";
		};
		gpio_ec_soc_pwr_good: ec_soc_pwr_good {
			gpios = <&gpiod 3 GPIO_OUTPUT_LOW>;
		};
		gpio_pcore_ocp_r_l: pcore_ocp_r_l {
			gpios = <&gpioa 5 GPIO_INPUT>;
		};
		gpio_usb_hub_fault_q_odl: usb_hub_fault_q_odl {
			gpios = <&gpioe 5 GPIO_INPUT_PULL_UP>;
		};
		gpio_pg_lpddr5_s3_od: pg_lpddr5_s3_od {
			gpios = <&gpio7 3 GPIO_INPUT>;
		};
		3axis_int_l {
			gpios = <&gpioa 2 GPIO_INPUT_PULL_UP>;
		};
		gpio_ec_soc_pwr_btn_l: ec_soc_pwr_btn_l {
			gpios = <&gpioa 7 GPIO_OUTPUT_HIGH>;
			enum-name = "GPIO_PCH_PWRBTN_L";
		};
		gpio_volup_btn_odl: volup_btn_odl {
			gpios = <&gpio6 7 GPIO_INPUT_PULL_UP>;
			enum-name = "GPIO_VOLUME_UP_L";
		};
		gpio_voldn_btn_odl: voldn_btn_odl {
			gpios = <&gpio7 0 GPIO_INPUT_PULL_UP>;
			enum-name = "GPIO_VOLUME_DOWN_L";
		};
		ec_sc_rst {
			gpios = <&gpiob 0 GPIO_OUTPUT_LOW>;
		};
		gpio_cbi_wp: ec_cbi_wp {
			gpios = <&gpio8 1 GPIO_OUTPUT_LOW>;
		};
		gpio_wp: ec_wp_l {
			gpios = <&gpiod 7 (GPIO_INPUT | GPIO_ACTIVE_LOW)>;
		};
		gpio_pg_lpddr5_s0_od: pg_lpddr5_s0_od {
			gpios = <&gpio6 0 GPIO_INPUT>;
		};
		ec_espi_rst_l {
			gpios = <&gpio5 4 GPIO_PULL_DOWN>;
		};
		gpio_accel_gyro_int_l: accel_gyro_int_l {
			gpios = <&gpioa 0 GPIO_INPUT>;
		};
		/* unimplemented GPIOs */
		entering-rw {
			enum-name = "GPIO_ENTERING_RW";
		};
		pch-sys-prwok {
			enum-name = "GPIO_PCH_SYS_PWROK";
		};
		ec_i2c_usb_a0_c0_scl {
			gpios = <&gpiob 5 GPIO_INPUT>;
		};
		ec_i2c_usb_a0_c0_sda {
			gpios = <&gpiob 4 GPIO_INPUT>;
		};
		ec_i2c_usb_a1_c1_scl {
			gpios = <&gpio9 0 GPIO_INPUT>;
		};
		ec_i2c_usb_a1_c1_sda {
			gpios = <&gpio8 7 GPIO_INPUT>;
		};
		ec_i2c_batt_scl {
			gpios = <&gpio9 2 (GPIO_INPUT | GPIO_VOLTAGE_1P8)>;
		};
		ec_i2c_batt_sda {
			gpios = <&gpio9 1 (GPIO_INPUT | GPIO_VOLTAGE_1P8)>;
		};
		ec_i2c_usbc_mux_scl {
			gpios = <&gpiod 1 GPIO_INPUT>;
		};
		ec_i2c_usbc_mux_sda {
			gpios = <&gpiod 0 GPIO_INPUT>;
		};
		ec_i2c_power_scl {
			gpios = <&gpiof 3 GPIO_INPUT>;
		};
		ec_i2c_power_sda {
			gpios = <&gpiof 2 GPIO_INPUT>;
		};
		ec_i2c_cbi_scl {
			gpios = <&gpio3 3 GPIO_INPUT>;
		};
		ec_i2c_cbi_sda {
			gpios = <&gpio3 6 GPIO_INPUT>;
		};
		ec_i2c_sensor_scl {
			gpios = <&gpioe 4 (GPIO_INPUT | GPIO_VOLTAGE_1P8)>;
		};
		ec_i2c_sensor_sda {
			gpios = <&gpioe 3 (GPIO_INPUT | GPIO_VOLTAGE_1P8)>;
		};
		ec_i2c_soc_sic {
			gpios = <&gpiob 3 (GPIO_INPUT | GPIO_VOLTAGE_1P8)>;
		};
		ec_i2c_soc_sid {
			gpios = <&gpiob 2 (GPIO_INPUT | GPIO_VOLTAGE_1P8)>;
		};
		en_kb_bl {
			gpios = <&gpio9 7 GPIO_OUTPUT_HIGH>;
			enum-name = "GPIO_EN_KEYBOARD_BACKLIGHT";
		};
		gpio_ec_kso_02_inv: ec_kso_02_inv {
			gpios = <&gpio1 7 (GPIO_OUTPUT_LOW | GPIO_ACTIVE_LOW)>;
		};
		tablet_mode_l {
			gpios = <&gpioc 1 GPIO_INPUT>;
			enum-name = "GPIO_TABLET_MODE_L";
		};
		ec_gpio56 {
			gpios = <&gpio5 6 GPIO_INPUT_PULL_UP>;
		};
		ec_flprg2 {
			gpios = <&gpio8 6 GPIO_INPUT_PULL_UP>;
		};

		usb_c0_tcpc_fastsw_ctl_en {
			gpios = <&ioex_c0_port0 4 GPIO_OUTPUT_LOW>;
			enum-name = "IOEX_USB_C0_TCPC_FASTSW_CTL_EN";
		};
		usb_c0_ppc_en_l {
			gpios = <&ioex_c0_port1 0 GPIO_OUTPUT_LOW>;
		};
		ioex_usb_c0_ilim_3a_en: usb_c0_ppc_ilim_3a_en {
			gpios = <&ioex_c0_port1 1 GPIO_OUTPUT_LOW>;
			enum-name = "IOEX_USB_C0_PPC_ILIM_3A_EN";
		};
		ioex_usb_c0_sbu_fault_odl: usb_c0_sbu_fault_odl {
			gpios = <&ioex_c0_port1 2 GPIO_INPUT>;
		};
		ioex_en_pp5000_usb_a0_vbus: en_pp5000_usb_a0_vbus {
			gpios = <&ioex_c0_port1 5 GPIO_OUTPUT_LOW>;
		};
		ioex_usb_a0_fault_odl: usb_a0_fault_odl {
			gpios = <&ioex_c0_port1 6 GPIO_INPUT>;
		};
		ioex_usb_c0_sbu_flip: usb_c0_sbu_flip {
			gpios = <&ioex_c0_port1 7 GPIO_OUTPUT_LOW>;
			enum-name = "IOEX_USB_C0_SBU_FLIP";
		};

		usb_a1_retimer_en {
			gpios = <&ioex_c1_port0 0 GPIO_OUTPUT_LOW>;
			enum-name = "IOEX_USB_A1_RETIMER_EN";
		};
		usb_a1_retimer_rst {
			gpios = <&ioex_c1_port0 1 GPIO_OUTPUT_LOW>;
		};
		usb_c1_in_hpd {
			gpios = <&ioex_c1_port0 3 GPIO_OUTPUT_LOW>;
			enum-name = "IOEX_USB_C1_HPD_IN_DB";
		};
		usb_c1_tcpc_fastsw_ctl_en {
			gpios = <&ioex_c1_port0 4 GPIO_OUTPUT_LOW>;
			enum-name = "IOEX_USB_C1_TCPC_FASTSW_CTL_EN";
		};
		usb_c1_ppc_en_l {
			gpios = <&ioex_c1_port1 0 GPIO_OUTPUT_LOW>;
		};
		usb_c1_ppc_ilim_3a_en {
			gpios = <&ioex_c1_port1 1 GPIO_OUTPUT_LOW>;
			enum-name = "IOEX_USB_C1_PPC_ILIM_3A_EN";
		};
		ioex_usb_c1_sbu_fault_odl: usb_c1_sbu_fault_odl {
			gpios = <&ioex_c1_port1 2 GPIO_INPUT>;
			enum-name = "IOEX_USB_C1_FAULT_ODL";
		};
		ioex_en_pp5000_usb_a1_vbus: en_pp5000_usb_a1_vbus {
			gpios = <&ioex_c1_port1 5 GPIO_OUTPUT_LOW>;
		};
		ioex_usb_a1_fault_db_odl: usb_a1_fault_db_odl {
			gpios = <&ioex_c1_port1 6 GPIO_INPUT>;
		};
		ioex_usb_c1_sbu_flip: usb_c1_sbu_flip {
			gpios = <&ioex_c1_port1 7 GPIO_OUTPUT_LOW>;
			enum-name = "IOEX_USB_C1_SBU_FLIP";
		};
	};

	usba-port-enable-list {
		compatible = "cros-ec,usba-port-enable-pins";
		enable-pins = <&ioex_en_pp5000_usb_a0_vbus
			       &ioex_en_pp5000_usb_a1_vbus>;
	};
};

/* PSL input pads*/
&psl_in1_gpd2 {
	/* MECH_PWR_BTN_ODL */
	psl-in-mode = "edge";
	psl-in-pol = "low-falling";
};

&psl_in2_gp00 {
	/* ACOK_OD */
	psl-in-mode = "edge";
	psl-in-pol = "high-rising";
};

&psl_in4_gp02 {
	/* LID_OPEN */
	psl-in-mode = "edge";
	psl-in-pol = "high-rising";
};

/* Power domain device controlled by PSL (Power Switch Logic) IO pads */
&power_ctrl_psl {
	status = "okay";
	pinctrl-names = "sleep";
	pinctrl-0 = <&psl_in1_gpd2 &psl_in2_gp00 &psl_in4_gp02>;
};

/* host interface */
&espi0 {
	status = "okay";
	pinctrl-0 = <&espi_lpc_gp46_47_51_52_53_54_55_57>;
	pinctrl-names = "default";
};
```

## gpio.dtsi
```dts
/* Copyright 2021 The ChromiumOS Authors
 * Use of this source code is governed by a BSD-style license that can be
 * found in the LICENSE file.
 */

/ {
	aliases {
		gpio-wp = &gpio_wp;
		gpio-cbi-wp = &gpio_cbi_wp;
		gpio-kbd-kso2 = &gpio_ec_kso_02_inv;
	};

	/* GPIOs shared by all boards */
	named-gpios {
		compatible = "named-gpios";

		ccd_mode_odl {
			gpios = <&gpioc 6 GPIO_ODR_HIGH>;
		};
		ec_gsc_packet_mode {
			gpios = <&gpiob 1 GPIO_OUTPUT_LOW>;
			enum-name = "GPIO_PACKET_MODE_EN";
		};
		gpio_mech_pwr_btn_odl: mech_pwr_btn_odl {
			gpios = <&gpiod 2 GPIO_INPUT>;
			enum-name = "GPIO_POWER_BUTTON_L";
		};
		gpio_slp_s3_l: slp_s3_l {
			gpios = <&gpio6 1 GPIO_INPUT>;
			enum-name = "GPIO_PCH_SLP_S3_L";
			alias = "GPIO_PCH_SLP_S0_L";
		};
		gpio_slp_s5_l: slp_s5_l {
			gpios = <&gpio7 2 GPIO_INPUT>;
			enum-name = "GPIO_PCH_SLP_S5_L";
		};
		gpio_pg_pwr_s5: pg_pwr_s5 {
			gpios = <&gpioc 0 GPIO_INPUT>;
			enum-name = "GPIO_S5_PGOOD";
		};
		gpio_s0_pgood: pg_pcore_s0_r_od {
			gpios = <&gpiob 6 GPIO_INPUT>;
			enum-name = "GPIO_S0_PGOOD";
		};
		gpio_acok_od: acok_od {
			gpios = <&gpio0 0 GPIO_INPUT>;
			enum-name = "GPIO_AC_PRESENT";
		};
		gpio_en_pwr_s5: en_pwr_s5 {
			gpios = <&gpiob 7 GPIO_OUTPUT_LOW>;
			enum-name = "GPIO_EN_PWR_A";
		};
		gpio_en_pwr_s0_r: en_pwr_s0_r {
			gpios = <&gpiof 1 GPIO_OUTPUT_LOW>;
		};
		gpio_en_pwr_pcore_s0_r: en_pwr_pcore_s0_r {
			gpios = <&gpioe 1 GPIO_OUTPUT_LOW>;
		};
		ec_sys_rst_l {
			gpios = <&gpio7 6 GPIO_ODR_HIGH>;
			enum-name = "GPIO_SYS_RESET_L";
		};
		gpio_ec_soc_rsmrst_l: ec_soc_rsmrst_l {
			gpios = <&gpioc 5 GPIO_OUTPUT_LOW>;
			enum-name = "GPIO_PCH_RSMRST_L";
		};
		gpio_ec_pch_wake_odl: ec_soc_wake_l {
			gpios = <&gpio0 3 GPIO_OUTPUT_HIGH>;
		};
		gpio_prochot_odl: prochot_odl {
			gpios = <&gpiod 5 GPIO_ODR_HIGH>;
			enum-name = "GPIO_CPU_PROCHOT";
		};
		soc_alert_ec_l {
			gpios = <&gpioe 2 GPIO_INPUT>;
		};
		gpio_usb_c0_tcpc_int_odl: usb_c0_tcpc_int_odl {
			gpios = <&gpioe 0 (GPIO_INPUT | GPIO_ACTIVE_LOW)>;
			enum-name = "GPIO_USB_C0_TCPC_INT_ODL";
		};
		gpio_usb_c1_tcpc_int_odl: usb_c1_tcpc_int_odl {
			gpios = <&gpioc 7 (GPIO_INPUT | GPIO_ACTIVE_LOW)>;
			enum-name = "GPIO_USB_C1_TCPC_INT_ODL";
		};
		gpio_usb_c0_ppc_int_odl: usb_c0_ppc_int_odl {
			gpios = <&gpio7 5 (GPIO_INPUT | GPIO_ACTIVE_LOW)>;
			enum-name = "GPIO_USB_C0_PPC_INT_ODL";
		};
		gpio_usb_c1_ppc_int_odl: usb_c1_ppc_int_odl {
			gpios = <&gpiod 4 (GPIO_INPUT | GPIO_ACTIVE_LOW)>;
			enum-name = "GPIO_USB_C1_PPC_INT_ODL";
		};
		gpio_usb_c0_bc12_int_odl: usb_c0_bc12_int_odl {
			gpios = <&gpioa 4 GPIO_INPUT_PULL_UP>;
			enum-name = "GPIO_USB_C0_BC12_INT_ODL";
		};
		gpio_usb_c1_bc12_int_odl: usb_c1_bc12_int_odl {
			gpios = <&gpio9 6 GPIO_INPUT_PULL_UP>;
			enum-name = "GPIO_USB_C1_BC12_INT_ODL";
		};
		gpio_usb_c0_tcpc_rst_l: usb_c0_tcpc_rst_l {
			gpios = <&gpio3 4 (GPIO_OUTPUT_HIGH | GPIO_ACTIVE_LOW)>;
			enum-name = "GPIO_USB_C0_TCPC_RST_L";
		};
		gpio_usb_c1_tcpc_rst_l: usb_c1_tcpc_rst_l {
			gpios = <&gpio3 7 (GPIO_OUTPUT_HIGH | GPIO_ACTIVE_LOW)>;
			enum-name = "GPIO_USB_C1_TCPC_RST_L";
		};
		usb_c0_hpd {
			gpios = <&gpiof 5 GPIO_OUTPUT_LOW>;
			enum-name = "GPIO_USB_C0_DP_HPD";
		};
		usb_c1_hpd {
			gpios = <&gpiof 4 GPIO_OUTPUT_LOW>;
			enum-name = "GPIO_USB_C1_DP_HPD";
		};
		gpio_lid_open: lid_open {
			gpios = <&gpio0 2 GPIO_INPUT>;
			enum-name = "GPIO_LID_OPEN";
		};
		gpio_ec_batt_pres_odl: ec_batt_pres_odl {
			gpios = <&gpio9 4 GPIO_INPUT>;
			enum-name = "GPIO_BATT_PRES_ODL";
		};
		gpio_ec_disable_disp_bl: ec_disable_disp_bl {
			gpios = <&gpioa 6 GPIO_OUTPUT_HIGH>;
			enum-name = "GPIO_ENABLE_BACKLIGHT_L";
		};
		gpio_usb_fault_odl: usb_fault_odl {
			gpios = <&gpio5 0 (GPIO_ODR_HIGH | GPIO_VOLTAGE_1P8)>;
		};
		gpio_en_pwr_s3: en_pwr_s3 {
			gpios = <&gpio7 4 GPIO_OUTPUT_LOW>;
		};
		gpio_pg_groupc_s0_od: pg_groupc_s0_od {
			gpios = <&gpiof 0 GPIO_INPUT>;
		};
		gpio_ec_i2c_usbc_pd_int: ec_i2c_usbc_pd_int {
			gpios = <&gpioa 3 GPIO_INPUT>;
		};
		gpio_soc_thermtrip_odl: soc_thermtrip_odl {
			gpios = <&gpio9 5 GPIO_INPUT>;
		};
		gpio_hub_rst: hub_rst {
			gpios = <&gpio6 6 GPIO_OUTPUT_HIGH>;
		};
		ec_soc_int_l {
			gpios = <&gpioa 1 GPIO_OUTPUT_HIGH>;
			enum-name = "GPIO_EC_INT_L";
		};
		gpio_ec_soc_pwr_good: ec_soc_pwr_good {
			gpios = <&gpiod 3 GPIO_OUTPUT_LOW>;
		};
		gpio_pcore_ocp_r_l: pcore_ocp_r_l {
			gpios = <&gpioa 5 GPIO_INPUT>;
		};
		gpio_usb_hub_fault_q_odl: usb_hub_fault_q_odl {
			gpios = <&gpioe 5 GPIO_INPUT_PULL_UP>;
		};
		gpio_pg_lpddr5_s3_od: pg_lpddr5_s3_od {
			gpios = <&gpio7 3 GPIO_INPUT>;
		};
		gpio_lid_accel_int_l: 3axis_int_l {
			gpios = <&gpioa 2 GPIO_INPUT_PULL_UP>;
		};
		gpio_ec_soc_pwr_btn_l: ec_soc_pwr_btn_l {
			gpios = <&gpioa 7 GPIO_OUTPUT_HIGH>;
			enum-name = "GPIO_PCH_PWRBTN_L";
		};
		gpio_volup_btn_odl: volup_btn_odl {
			gpios = <&gpio6 7 GPIO_INPUT_PULL_UP>;
			enum-name = "GPIO_VOLUME_UP_L";
		};
		gpio_voldn_btn_odl: voldn_btn_odl {
			gpios = <&gpio7 0 GPIO_INPUT_PULL_UP>;
			enum-name = "GPIO_VOLUME_DOWN_L";
		};
		ec_sc_rst {
			gpios = <&gpiob 0 GPIO_OUTPUT_LOW>;
		};
		gpio_cbi_wp: ec_cbi_wp {
			gpios = <&gpio8 1 GPIO_OUTPUT_LOW>;
		};
		gpio_wp: ec_wp_l {
			gpios = <&gpiod 7 (GPIO_INPUT | GPIO_ACTIVE_LOW)>;
		};
		gpio_pg_lpddr5_s0_od: pg_lpddr5_s0_od {
			gpios = <&gpio6 0 GPIO_INPUT>;
		};
		ec_espi_rst_l {
			gpios = <&gpio5 4 GPIO_PULL_DOWN>;
		};
		gpio_accel_gyro_int_l: accel_gyro_int_l {
			gpios = <&gpioa 0 GPIO_INPUT>;
		};
		/* unimplemented GPIOs */
		entering-rw {
			enum-name = "GPIO_ENTERING_RW";
		};
		pch-sys-prwok {
			enum-name = "GPIO_PCH_SYS_PWROK";
		};
		ec_i2c_usb_a0_c0_scl {
			gpios = <&gpiob 5 GPIO_INPUT>;
		};
		ec_i2c_usb_a0_c0_sda {
			gpios = <&gpiob 4 GPIO_INPUT>;
		};
		ec_i2c_usb_a1_c1_scl {
			gpios = <&gpio9 0 GPIO_INPUT>;
		};
		ec_i2c_usb_a1_c1_sda {
			gpios = <&gpio8 7 GPIO_INPUT>;
		};
		ec_i2c_batt_scl {
			gpios = <&gpio9 2 (GPIO_INPUT | GPIO_VOLTAGE_1P8)>;
		};
		ec_i2c_batt_sda {
			gpios = <&gpio9 1 (GPIO_INPUT | GPIO_VOLTAGE_1P8)>;
		};
		ec_i2c_usbc_mux_scl {
			gpios = <&gpiod 1 GPIO_INPUT>;
		};
		ec_i2c_usbc_mux_sda {
			gpios = <&gpiod 0 GPIO_INPUT>;
		};
		ec_i2c_power_scl {
			gpios = <&gpiof 3 GPIO_INPUT>;
		};
		ec_i2c_power_sda {
			gpios = <&gpiof 2 GPIO_INPUT>;
		};
		ec_i2c_cbi_scl {
			gpios = <&gpio3 3 GPIO_INPUT>;
		};
		ec_i2c_cbi_sda {
			gpios = <&gpio3 6 GPIO_INPUT>;
		};
		ec_i2c_sensor_scl {
			gpios = <&gpioe 4 (GPIO_INPUT | GPIO_VOLTAGE_1P8)>;
		};
		ec_i2c_sensor_sda {
			gpios = <&gpioe 3 (GPIO_INPUT | GPIO_VOLTAGE_1P8)>;
		};
		ec_i2c_soc_sic {
			gpios = <&gpiob 3 (GPIO_INPUT | GPIO_VOLTAGE_1P8)>;
		};
		ec_i2c_soc_sid {
			gpios = <&gpiob 2 (GPIO_INPUT | GPIO_VOLTAGE_1P8)>;
		};
		en_kb_bl {
			gpios = <&gpio9 7 GPIO_OUTPUT_HIGH>;
			enum-name = "GPIO_EN_KEYBOARD_BACKLIGHT";
		};
		gpio_ec_kso_02_inv: ec_kso_02_inv {
			gpios = <&gpio1 7 (GPIO_OUTPUT | GPIO_ACTIVE_HIGH)>;
		};
		tablet_mode_l {
			gpios = <&gpioc 1 GPIO_INPUT>;
			enum-name = "GPIO_TABLET_MODE_L";
		};
		ec_flprg2 {
			gpios = <&gpio8 6 GPIO_INPUT_PULL_UP>;
		};

		usb_c0_tcpc_fastsw_ctl_en {
			gpios = <&ioex_c0_port0 4 GPIO_OUTPUT_LOW>;
			enum-name = "IOEX_USB_C0_TCPC_FASTSW_CTL_EN";
		};
		usb_c0_ppc_en_l {
			gpios = <&ioex_c0_port1 0 GPIO_OUTPUT_LOW>;
		};
		ioex_usb_c0_ilim_3a_en: usb_c0_ppc_ilim_3a_en {
			gpios = <&ioex_c0_port1 1 GPIO_OUTPUT_LOW>;
			enum-name = "IOEX_USB_C0_PPC_ILIM_3A_EN";
		};
		ioex_usb_c0_sbu_fault_odl: usb_c0_sbu_fault_odl {
			gpios = <&ioex_c0_port1 2 GPIO_INPUT>;
		};
		ioex_en_pp5000_usb_a0_vbus: en_pp5000_usb_a0_vbus {
			gpios = <&ioex_c0_port1 5 GPIO_OUTPUT_LOW>;
		};
		ioex_usb_a0_fault_odl: usb_a0_fault_odl {
			gpios = <&ioex_c0_port1 6 GPIO_INPUT>;
		};
		ioex_usb_c0_sbu_flip: usb_c0_sbu_flip {
			gpios = <&ioex_c0_port1 7 GPIO_OUTPUT_LOW>;
			enum-name = "IOEX_USB_C0_SBU_FLIP";
		};

		usb_a1_retimer_en {
			gpios = <&ioex_c1_port0 0 GPIO_OUTPUT_LOW>;
			enum-name = "IOEX_USB_A1_RETIMER_EN";
		};
		usb_a1_retimer_rst {
			gpios = <&ioex_c1_port0 1 GPIO_OUTPUT_LOW>;
		};
		usb_c1_in_hpd {
			gpios = <&ioex_c1_port0 3 GPIO_OUTPUT_LOW>;
			enum-name = "IOEX_USB_C1_HPD_IN_DB";
		};
		usb_c1_tcpc_fastsw_ctl_en {
			gpios = <&ioex_c1_port0 4 GPIO_OUTPUT_LOW>;
			enum-name = "IOEX_USB_C1_TCPC_FASTSW_CTL_EN";
		};
		usb_c1_ppc_en_l {
			gpios = <&ioex_c1_port1 0 GPIO_OUTPUT_LOW>;
		};
		usb_c1_ppc_ilim_3a_en {
			gpios = <&ioex_c1_port1 1 GPIO_OUTPUT_LOW>;
			enum-name = "IOEX_USB_C1_PPC_ILIM_3A_EN";
		};
		ioex_usb_c1_sbu_fault_odl: usb_c1_sbu_fault_odl {
			gpios = <&ioex_c1_port1 2 GPIO_INPUT>;
			enum-name = "IOEX_USB_C1_FAULT_ODL";
		};
		ioex_en_pp5000_usb_a1_vbus: en_pp5000_usb_a1_vbus {
			gpios = <&ioex_c1_port1 5 GPIO_OUTPUT_LOW>;
		};
		ioex_usb_a1_fault_db_odl: usb_a1_fault_db_odl {
			gpios = <&ioex_c1_port1 6 GPIO_INPUT>;
		};
		ioex_usb_c1_sbu_flip: usb_c1_sbu_flip {
			gpios = <&ioex_c1_port1 7 GPIO_OUTPUT_LOW>;
			enum-name = "IOEX_USB_C1_SBU_FLIP";
		};

		/* STB dumping GPIOs */
		gpio_ec_sfh_int_h: ec_sfh_int_h {
			gpios = <&gpio9 3 GPIO_OUTPUT_LOW>;
		};
		gpio_sfh_ec_int_h: sfh_ec_int_h {
			gpios = <&gpio5 6 GPIO_INPUT>;
		};
	};

	usba-port-enable-list {
		compatible = "cros-ec,usba-port-enable-pins";
		enable-pins = <&ioex_en_pp5000_usb_a0_vbus
			       &ioex_en_pp5000_usb_a1_vbus>;
	};
};

/* PSL input pads*/
&psl_in1_gpd2 {
	/* MECH_PWR_BTN_ODL */
	psl-in-mode = "edge";
	psl-in-pol = "low-falling";
};

&psl_in2_gp00 {
	/* ACOK_OD */
	psl-in-mode = "edge";
	psl-in-pol = "high-rising";
};

&psl_in4_gp02 {
	/* LID_OPEN */
	psl-in-mode = "edge";
	psl-in-pol = "high-rising";
};

/* Power domain device controlled by PSL (Power Switch Logic) IO pads */
&power_ctrl_psl {
	status = "okay";
	pinctrl-names = "sleep";
	pinctrl-0 = <&psl_in1_gpd2 &psl_in2_gp00 &psl_in4_gp02>;
};

/* host interface */
&espi0 {
	status = "okay";
	pinctrl-0 = <&espi_lpc_gp46_47_51_52_53_54_55_57>;
	pinctrl-names = "default";
};
```

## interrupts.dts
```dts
/* Copyright 2022 The ChromiumOS Authors
 * Use of this source code is governed by a BSD-style license that can be
 * found in the LICENSE file.
 */

/ {
	gpio-interrupts {
		compatible = "cros-ec,gpio-interrupts";

		int_lid_open: lid_open {
			irq-pin = <&gpio_lid_open>;
			flags = <GPIO_INT_EDGE_BOTH>;
			handler = "lid_interrupt";
		};
		int_ac_present: ac_present {
			irq-pin = <&gpio_acok_od>;
			flags = <GPIO_INT_EDGE_BOTH>;
			handler = "extpower_interrupt";
		};
		int_power_button: power_button {
			irq-pin = <&gpio_mech_pwr_btn_odl>;
			flags = <GPIO_INT_EDGE_BOTH>;
			handler = "power_button_interrupt";
		};
		int_slp_s3: slp_s3 {
			irq-pin = <&gpio_slp_s3_l>;
			flags = <GPIO_INT_EDGE_BOTH>;
			handler = "baseboard_en_pwr_s0";
		};
		int_slp_s5: slp_s5 {
			irq-pin = <&gpio_slp_s5_l>;
			flags = <GPIO_INT_EDGE_BOTH>;
			handler = "baseboard_set_en_pwr_s3";
		};
		int_s5_pgood: s5_pgood {
			irq-pin = <&gpio_pg_pwr_s5>;
			flags = <GPIO_INT_EDGE_BOTH>;
			handler = "baseboard_s5_pgood";
		};
		int_pg_groupc_s0: pg_groupc_s0 {
			irq-pin = <&gpio_pg_groupc_s0_od>;
			flags = <GPIO_INT_EDGE_BOTH>;
			handler = "baseboard_set_en_pwr_pcore";
		};
		int_pg_lpddr_s3: pg_lpddr_s3 {
			irq-pin = <&gpio_pg_lpddr5_s3_od>;
			flags = <GPIO_INT_EDGE_BOTH>;
			handler = "baseboard_set_en_pwr_pcore";
		};
		int_pg_lpddr_s0: pg_lpddr_s0 {
			irq-pin = <&gpio_pg_lpddr5_s0_od>;
			flags = <GPIO_INT_EDGE_BOTH>;
			handler = "baseboard_set_soc_pwr_pgood";
		};
		int_s0_pgood: s0_pgood {
			irq-pin = <&gpio_s0_pgood>;
			flags = <GPIO_INT_EDGE_BOTH>;
			handler = "baseboard_s0_pgood";
		};
		int_soc_thermtrip: soc_thermtrip {
			irq-pin = <&gpio_soc_thermtrip_odl>;
			flags = <GPIO_INT_EDGE_FALLING>;
			handler = "baseboard_soc_thermtrip";
		};
		int_soc_pcore_ocp: soc_pcore_ocp {
			irq-pin = <&gpio_pcore_ocp_r_l>;
			flags = <GPIO_INT_EDGE_FALLING>;
			handler = "baseboard_soc_pcore_ocp";
		};
		int_volume_up: volume_up {
			irq-pin = <&gpio_volup_btn_odl>;
			flags = <GPIO_INT_EDGE_BOTH>;
			handler = "button_interrupt";
		};
		int_volume_down: volume_down {
			irq-pin = <&gpio_voldn_btn_odl>;
			flags = <GPIO_INT_EDGE_BOTH>;
			handler = "button_interrupt";
		};
		int_usb_a0_fault: a0_fault {
			irq-pin = <&ioex_usb_a0_fault_odl>;
			flags = <GPIO_INT_EDGE_BOTH>;
			handler = "usb_fault_interrupt";
		};
		int_usb_a1_fault: a1_fault {
			irq-pin = <&ioex_usb_a1_fault_db_odl>;
			flags = <GPIO_INT_EDGE_BOTH>;
			handler = "usb_fault_interrupt";
		};
		int_usb_c0_sbu_fault: c0_sbu_fault {
			irq-pin = <&ioex_usb_c0_sbu_fault_odl>;
			flags = <GPIO_INT_EDGE_FALLING>;
			handler = "sbu_fault_interrupt";
		};
		int_usb_c1_sbu_fault: c1_sbu_fault {
			irq-pin = <&ioex_usb_c1_sbu_fault_odl>;
			flags = <GPIO_INT_EDGE_FALLING>;
			handler = "sbu_fault_interrupt";
		};
		int_usb_c0_tcpc: usb_c0_tcpc {
			irq-pin = <&gpio_usb_c0_tcpc_int_odl>;
			flags = <GPIO_INT_EDGE_FALLING>;
			handler = "tcpc_alert_event";
		};
		int_usb_c1_tcpc: usb_c1_tcpc {
			irq-pin = <&gpio_usb_c1_tcpc_int_odl>;
			flags = <GPIO_INT_EDGE_FALLING>;
			handler = "tcpc_alert_event";
		};
		int_usb_c0_ppc: usb_c0_ppc {
			irq-pin = <&gpio_usb_c0_ppc_int_odl>;
			flags = <GPIO_INT_EDGE_FALLING>;
			handler = "ppc_interrupt";
		};
		int_usb_c1_ppc: usb_c1_ppc {
			irq-pin = <&gpio_usb_c1_ppc_int_odl>;
			flags = <GPIO_INT_EDGE_FALLING>;
			handler = "ppc_interrupt";
		};
		int_usb_c0_bc12: usb_c0_bc12 {
			irq-pin = <&gpio_usb_c0_bc12_int_odl>;
			flags = <GPIO_INT_EDGE_FALLING>;
			handler = "bc12_interrupt";
		};
		int_usb_c1_bc12: usb_c1_bc12 {
			irq-pin = <&gpio_usb_c1_bc12_int_odl>;
			flags = <GPIO_INT_EDGE_FALLING>;
			handler = "bc12_interrupt";
		};
		int_usb_hub_fault: hub_fault {
			irq-pin = <&gpio_usb_hub_fault_q_odl>;
			flags = <GPIO_INT_EDGE_BOTH>;
			handler = "usb_fault_interrupt";
		};
		int_usb_pd_soc: usb_pd_soc {
			irq-pin = <&gpio_ec_i2c_usbc_pd_int>;
			flags = <GPIO_INT_EDGE_FALLING>;
			handler = "usb_pd_soc_interrupt";
		};
		int_accel_gyro: accel_gyro {
			irq-pin = <&gpio_accel_gyro_int_l>;
			flags = <GPIO_INT_EDGE_FALLING>;
			handler = "bmi3xx_interrupt";
		};
	};
};
```

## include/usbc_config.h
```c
/* Copyright 2023 The ChromiumOS Authors
 * Use of this source code is governed by a BSD-style license that can be
 * found in the LICENSE file.
 */

/* Common definitions to help with tests. */

#ifndef __SKYRIM_USBC_CONFIG_H
#define __SKYRIM_USBC_CONFIG_H

#define SKYRIM_BC12_MIN_VOLTAGE 4500
#define SKYRIM_SAFE_RESET_VBUS_MV 5000

#endif /* __SKYRIM_USBC_CONFIG_H */
```

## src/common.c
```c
/* Copyright 2022 The ChromiumOS Authors
 * Use of this source code is governed by a BSD-style license that can be
 * found in the LICENSE file.
 */

#include <zephyr/logging/log.h>

LOG_MODULE_REGISTER(skyrim, CONFIG_SKYRIM_LOG_LEVEL);
```

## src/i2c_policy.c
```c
/* Copyright 2023 The ChromiumOS Authors
 * Use of this source code is governed by a BSD-style license that can be
 * found in the LICENSE file.
 */

#include "i2c.h"

int board_allow_i2c_passthru(const struct i2c_cmd_desc_t *cmd_desc)
{
	/* Passthrough isn't used on Skyrim. */
	return 0;
}
```

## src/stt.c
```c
/* Copyright 2022 The ChromiumOS Authors
 * Use of this source code is governed by a BSD-style license that can be
 * found in the LICENSE file.
 */

/* Support code for STT temperature reporting */

#include "chipset.h"
#include "temp_sensor/f75303.h"
#include "temp_sensor/pct2075.h"
#include "temp_sensor/temp_sensor.h"

int board_get_soc_temp_mk(int *temp_mk)
{
	if (chipset_in_state(CHIPSET_STATE_HARD_OFF))
		return EC_ERROR_NOT_POWERED;

#ifdef CONFIG_TEMP_SENSOR_PCT2075
	return pct2075_get_val_mk(PCT2075_SENSOR_ID(DT_NODELABEL(soc_pct2075)),
				  temp_mk);
#else
	return f75303_get_val_mk(F75303_SENSOR_ID(DT_NODELABEL(f75303_local)),
				 temp_mk);
#endif
}

int board_get_ambient_temp_mk(int *temp_mk)
{
	if (chipset_in_state(CHIPSET_STATE_HARD_OFF))
		return EC_ERROR_NOT_POWERED;

#ifdef CONFIG_TEMP_SENSOR_PCT2075
	return pct2075_get_val_mk(PCT2075_SENSOR_ID(DT_NODELABEL(amb_pct2075)),
				  temp_mk);
#else
	return f75303_get_val_mk(
		F75303_SENSOR_ID(DT_NODELABEL(f75303_remote_1)), temp_mk);
#endif
}
```
